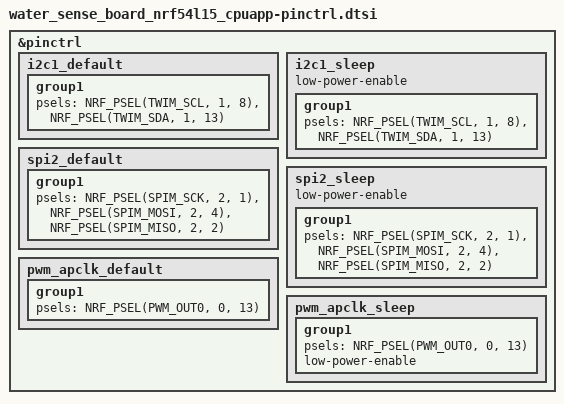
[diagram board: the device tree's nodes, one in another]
/*
 * Pin assignments — all from Victor, unchanged from the original board file
 * except for the AP_CLK group, which is new.
 *
 *   SCL      P1.08      SDA      P1.13
 *   SCK      P2.01      SDI      P2.04      SDO      P2.02
 *   CS       P0.00      — driven in software from the port file, so it is
 *                         deliberately NOT a pinctrl signal. On nRF, chip
 *                         select never is: SPIM does not drive it. That is also
 *                         why CS can sit on P0 while the SPI signals are on P2:
 *                         a plain GPIO has no power-domain tie to the
 *                         peripheral, whereas a pinctrl signal does.
 *   AP_CLK   P0.13      — INVALID. P0 has 7 pins on this SoC (P0.00..P0.06),
 *                         so P0.13 does not exist. The consuming pwm20 node is
 *                         disabled until Victor supplies a real pin; see the
 *                         long note there.
 *
 * SPDX-License-Identifier: Apache-2.0
 */

&pinctrl {

	i2c1_default: i2c1_default {
		group1 {
			psels = <NRF_PSEL(TWIM_SCL, 1, 8)>,
				<NRF_PSEL(TWIM_SDA, 1, 13)>;
		};
	};

	i2c1_sleep: i2c1_sleep {
		group1 {
			psels = <NRF_PSEL(TWIM_SCL, 1, 8)>,
				<NRF_PSEL(TWIM_SDA, 1, 13)>;
		};
		low-power-enable;
	};

	spi2_default: spi2_default {
		group1 {
			psels = <NRF_PSEL(SPIM_SCK, 2, 1)>,
				<NRF_PSEL(SPIM_MOSI, 2, 4)>,
				<NRF_PSEL(SPIM_MISO, 2, 2)>;
		};
	};

	spi2_sleep: spi2_sleep {
		group1 {
			psels = <NRF_PSEL(SPIM_SCK, 2, 1)>,
				<NRF_PSEL(SPIM_MOSI, 2, 4)>,
				<NRF_PSEL(SPIM_MISO, 2, 2)>;
		};
		low-power-enable;
	};

	/*
	 * AP_CLK — 8 MHz to the VL53L9CX.
	 *
	 * P0.13 BELOW IS NOT A REAL PIN and this group is not in use: gpio0 has
	 * ngpios = <7> on this SoC. It is left here, referenced only by a
	 * disabled node, so the intent is visible and one edit revives it.
	 *
	 * Two constraints on the replacement pin:
	 *   - it must exist: P0.00-P0.06, P1.00-P1.15, P2.00-P2.10
	 *   - it must be on P1 or P2 if PWM drives it. PWM_OUT never appears on
	 *     port 0 in Nordic's own boards, and pwm20/21/22 are 20-domain parts
	 *     while P0 is 30-domain.
	 *
	 * NOTE this would NOT have failed at build time. NRF_PSEL() only encodes
	 * port and pin into an integer; nothing checks the pin exists. It would
	 * have built, run, and produced no clock — and a VL53L9CX with no clock
	 * does not acknowledge its I2C address, which reads as a dead sensor.
	 */
	pwm_apclk_default: pwm_apclk_default {
		group1 {
			psels = <NRF_PSEL(PWM_OUT0, 0, 13)>;
		};
	};

	pwm_apclk_sleep: pwm_apclk_sleep {
		group1 {
			psels = <NRF_PSEL(PWM_OUT0, 0, 13)>;
			low-power-enable;
		};
	};
};
